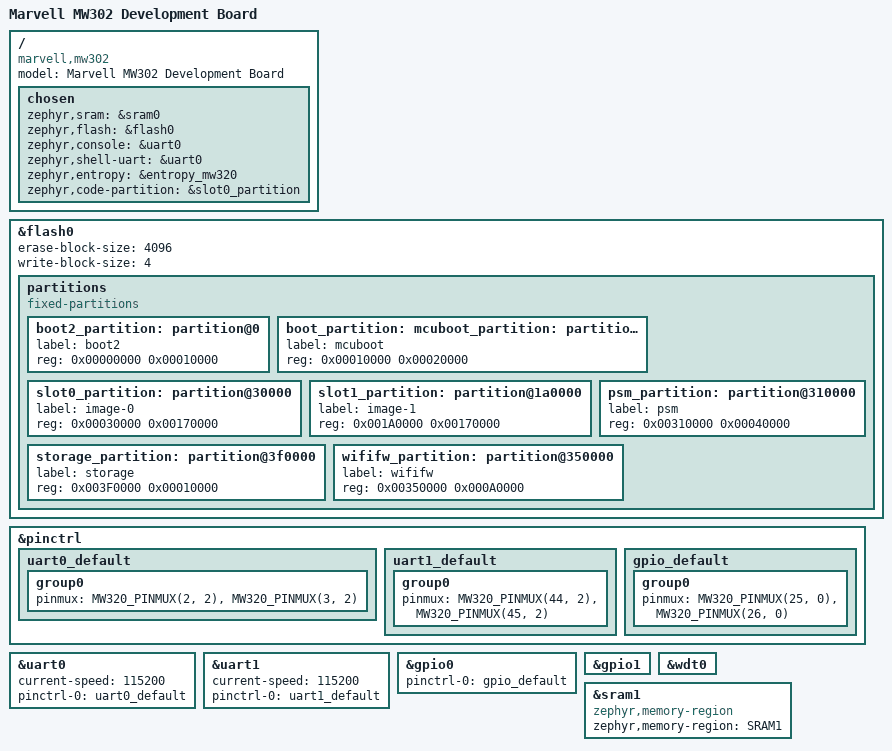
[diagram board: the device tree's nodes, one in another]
/dts-v1/;
#include "../../../soc/nxp/88mw320/88mw320.dtsi"
#include <dt-bindings/pinctrl/mw320-pinctrl.h>

/ {
	model = "Marvell MW302 Development Board";
	compatible = "marvell,mw302", "nxp,88mw320";

	chosen {
		zephyr,sram = &sram0;
		zephyr,flash = &flash0;
		zephyr,console = &uart0;
		zephyr,shell-uart = &uart0;
		zephyr,entropy = &entropy_mw320;
		zephyr,code-partition = &slot0_partition;
	};
};

&flash0 {
	erase-block-size = <4096>;
	write-block-size = <4>;
	partitions {
		compatible = "fixed-partitions";
		#address-cells = <1>;
		#size-cells = <1>;

        /* these MUST match board/flash-layout.txt */
		boot2_partition: partition@0 {
			label = "boot2";
			reg = <0x00000000 0x00010000>;
		};
		boot_partition: mcuboot_partition: partition@10000 {
			label = "mcuboot";
			reg = <0x00010000 0x00020000>;
		};
		slot0_partition: partition@30000 {
			label = "image-0";
			reg = <0x00030000 0x00170000>;
		};
		slot1_partition: partition@1a0000 {
			label = "image-1";
			reg = <0x001A0000 0x00170000>;
		};
		psm_partition: partition@310000 {
			label = "psm";
			reg = <0x00310000 0x00040000>;
		};
		storage_partition: partition@3f0000 {
			label = "storage";
			reg = <0x003F0000 0x00010000>;
		};
		wififw_partition: partition@350000 {
			label = "wififw";
			reg = <0x00350000 0x000A0000>;
		};
	};
};

&pinctrl {
	uart0_default: uart0_default {
		group0 {
			pinmux = <MW320_PINMUX(2, 2)>,  /* UART0 TX */
			         <MW320_PINMUX(3, 2)>;  /* UART0 RX */
		};
	};

	uart1_default: uart1_default {
		group0 {
			pinmux = <MW320_PINMUX(44, 2)>, /* UART1 TX */
			         <MW320_PINMUX(45, 2)>; /* UART1 RX */
		};
	};

	gpio_default: gpio_default {
		group0 {
			pinmux = <MW320_PINMUX(25, 0)>, /* XTAL32K IN */
			         <MW320_PINMUX(26, 0)>; /* XTAL32K OUT */
		};
	};
};

&uart0 {
	status = "okay";
	current-speed = <115200>;
	pinctrl-0 = <&uart0_default>;
	pinctrl-names = "default";
};

&uart1 {
	status = "okay";
	current-speed = <115200>;
	pinctrl-0 = <&uart1_default>;
	pinctrl-names = "default";
};

&gpio0 {
	status = "okay";
	pinctrl-0 = <&gpio_default>;
	pinctrl-names = "default";
};

&gpio1 {
	status = "okay";
};

&wdt0 {
	status = "okay";
};

&sram1 {
	compatible = "zephyr,memory-region", "mmio-sram";
	zephyr,memory-region = "SRAM1";
};
